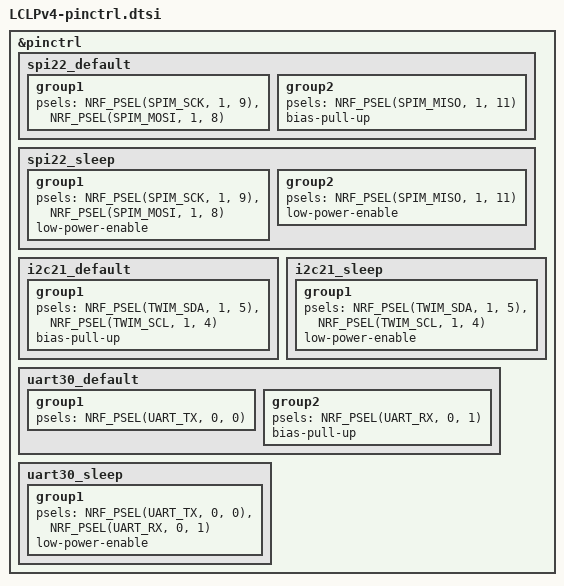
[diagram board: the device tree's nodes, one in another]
&pinctrl {
 /* ---- SPI22 (LoRa + SD Card) ---- */
    spi22_default: spi22_default {
        group1 {
            psels = <NRF_PSEL(SPIM_SCK, 1, 9)>,
                    <NRF_PSEL(SPIM_MOSI, 1, 8)>;
        };
        group2 {
            psels = <NRF_PSEL(SPIM_MISO, 1, 11)>;
            bias-pull-up;
        };
    };

    spi22_sleep: spi22_sleep {
        group1 {
            psels = <NRF_PSEL(SPIM_SCK, 1, 9)>,
                    <NRF_PSEL(SPIM_MOSI, 1, 8)>;
            low-power-enable;
        };
        group2 {
            psels = <NRF_PSEL(SPIM_MISO, 1, 11)>;
            low-power-enable;
        };
    };

    /* ---- I2C21 (NPM1300) ---- */
    i2c21_default: i2c21_default {
        group1 {
            psels = <NRF_PSEL(TWIM_SDA, 1, 5)>,
                    <NRF_PSEL(TWIM_SCL, 1, 4)>;
            bias-pull-up;
        };
    };

    i2c21_sleep: i2c21_sleep {
        group1 {
            psels = <NRF_PSEL(TWIM_SDA, 1, 5)>,
                    <NRF_PSEL(TWIM_SCL, 1, 4)>;
            low-power-enable;
        };
    };

    uart30_default: uart30_default {
        group1 {
            psels = <NRF_PSEL(UART_TX, 0, 0)>;  /* substitui pelo teu pino TX */
        };
        group2 {
            psels = <NRF_PSEL(UART_RX, 0, 1)>;  /* substitui pelo teu pino RX */
            bias-pull-up;
        };
    };
    uart30_sleep: uart30_sleep {
        group1 {
            psels = <NRF_PSEL(UART_TX, 0, 0)>,
                    <NRF_PSEL(UART_RX, 0, 1)>;
            low-power-enable;
        };
    };
};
